# AST2600 register map
File version: 1.1
CPU: CM3 r1p0, little endian, no MPU, no FPU, 3 interrupt priority bits
Registers are 32-bit, read-write, reset 0x0 unless marked. A register's access mark holds for its fields unless they carry their own. Offsets are from the block's base; [hi:lo] are bit positions; lines under a group give offsets from that group; {n}, {i} and the like mark numbered series.

## SCB — System Control Block
Base 0xE000ED00
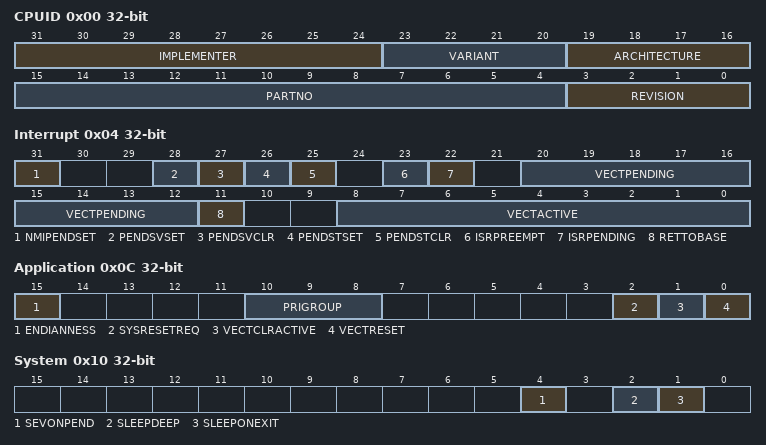
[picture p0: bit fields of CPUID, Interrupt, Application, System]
0x00 CPUID Base Register ro — Provides identification information for the processor
  [31:24] IMPLEMENTER — Implementer code assigned by ARM
  [23:20] VARIANT — IMPLEMENTATION DEFINED variant number
  [19:16] ARCHITECTURE — Reads as 0xF
  [15:4] PARTNO — IMPLEMENTATION DEFINED part number
  [3:0] REVISION — IMPLEMENTATION DEFINED revision number
0x04 Interrupt Control and State Register — Provides software control of the NMI, PendSV, and SysTick exceptions, and provides interrupt status information
  [31] NMIPENDSET — On writes, makes the NMI exception active
  [28] PENDSVSET — On writes, sets the PendSV exception as pending
  [27] PENDSVCLR — Removes the pending status of the PendSV exception
  [26] PENDSTSET — On writes, sets the SysTick exception as pending
  [25] PENDSTCLR — Removes the pending status of the SysTick exception
  [23] ISRPREEMPT — Indicates whether a pending exception will be serviced on exit from debug halt state
  [22] ISRPENDING — Indicates whether an external interrupt, generated by the NVIC, is pending
  [20:12] VECTPENDING — The exception number of the highest priority pending and enabled interrupt
  [11] RETTOBASE — In Handler mode, indicates whether there is an active exception other than the exception indicated by the current value of the IPSR
  [8:0] VECTACTIVE — The exception number of the current executing exception
0x08 Vector Table Offset Register — Holds the vector table address
  [31:7] TBLOFF — Bits[31:7] of the vector table address
0x0C Application Interrupt and Reset Control Register — Sets or returns interrupt control data
  [15] ENDIANNESS — Indicates the memory system endianness
  [10:8] PRIGROUP — Priority grouping, indicates the binary point position
  [2] SYSRESETREQ — System Reset Request
  [1] VECTCLRACTIVE — Writing 1 to this bit clears all active state information for fixed and configurable exceptions
  [0] VECTRESET — Writing 1 to this bit causes a local system reset
0x10 System Control Register — Sets or returns system control data
  [4] SEVONPEND — Determines whether an interrupt transition from inactive state to pending state is a wakeup event
  [2] SLEEPDEEP — Provides a qualifying hint indicating that waking from sleep might take longer
  [1] SLEEPONEXIT — Determines whether, on an exit from an ISR that returns to the base level of execution priority, the processor enters a sleep state
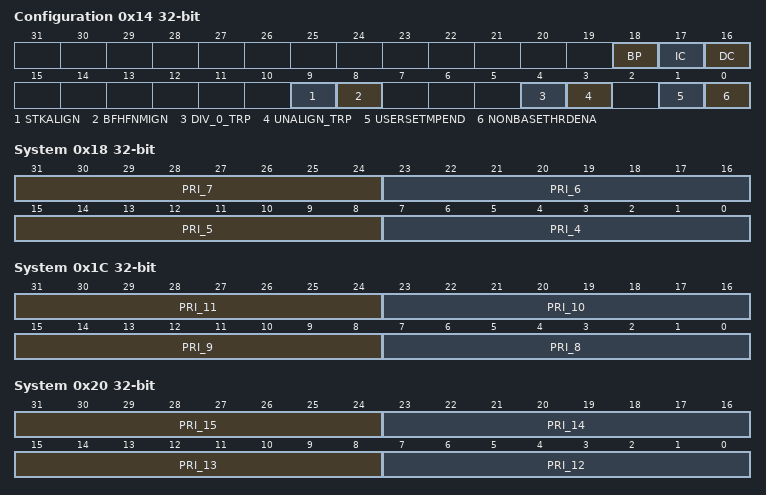
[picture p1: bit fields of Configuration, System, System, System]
0x14 Configuration and Control Register — Sets or returns configuration and control data, and provides control over caching and branch prediction
  [18] BP — Branch prediction enable bit
  [17] IC — Instruction cache enable bit
  [16] DC — Cache enable bit
  [9] STKALIGN — Determines whether the exception entry sequence guarantees 8-byte stack frame alignment, adjusting the SP if necessary before saving state
  [8] BFHFNMIGN — Determines the effect of precise data access faults on handlers running at priority -1 or priority -2
  [4] DIV_0_TRP — Controls the trap on divide by 0
  [3] UNALIGN_TRP — Controls the trapping of unaligned word or halfword accesses
  [1] USERSETMPEND — Controls whether unprivileged software can access the STIR
  [0] NONBASETHRDENA — Controls whether the processor can enter Thread mode with exceptions active
0x18 System Handler Priority Register 1 — Sets or returns priority for system handlers 4-7
  [31:24] PRI_7 — Reserved for priority of system handler 7
  [23:16] PRI_6 — Priority of system handler 6, UsageFault
  [15:8] PRI_5 — Priority of system handler 5, BusFault
  [7:0] PRI_4 — Priority of system handler 4, MemManage
0x1C System Handler Priority Register 2 — Sets or returns priority for system handlers 8-11
  [31:24] PRI_11 — Priority of system handler 11, SVCall
  [23:16] PRI_10 — Reserved for priority of system handler 10
  [15:8] PRI_9 — Reserved for priority of system handler 9
  [7:0] PRI_8 — Reserved for priority of system handler 8
0x20 System Handler Priority Register 3 — Sets or returns priority for system handlers 12-15
  [31:24] PRI_15 — Priority of system handler 15, SysTick
  [23:16] PRI_14 — Priority of system handler 14, PendSV
  [15:8] PRI_13 — Reserved for priority of system handler 13
  [7:0] PRI_12 — Priority of system handler 12, DebugMonitor
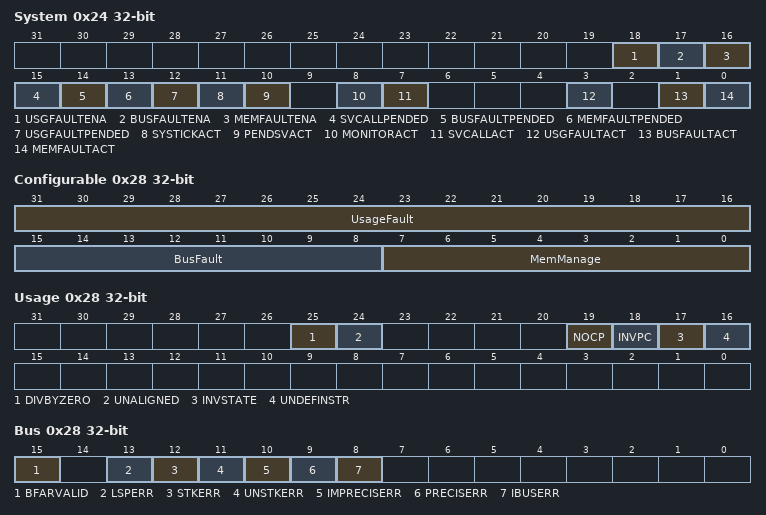
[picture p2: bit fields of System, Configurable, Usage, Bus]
0x24 System Handler Control and State Register — Controls and provides the active and pending status of system exceptions
  [18] USGFAULTENA — UsageFault exception enable
  [17] BUSFAULTENA — BusFault exception enable
  [16] MEMFAULTENA — MemManage exception enable
  [15] SVCALLPENDED — SVCall exception pended state
  [14] BUSFAULTPENDED — BusFault exception pended state
  [13] MEMFAULTPENDED — MemManage exception pended state
  [12] USGFAULTPENDED — UsageFault exception pended state
  [11] SYSTICKACT — SysTick exception active state
  [10] PENDSVACT — PendSV exception active state
  [8] MONITORACT — DebugMonitor exception active state
  [7] SVCALLACT — SVCall exception active state
  [3] USGFAULTACT — UsageFault exception active state
  [1] BUSFAULTACT — BusFault exception active state
  [0] MEMFAULTACT — MemManage exception active state
0x28 Configurable Fault Status Register — Contains the three Configurable Fault Status Registers
  [31:16] UsageFault — Provides information on UsageFault exceptions
  [15:8] BusFault — Provides information on BusFault exceptions
  [7:0] MemManage — Provides information on MemManage exceptions
0x28 Usage Fault Status Register — Provides information on UsageFault exceptions
  [25] DIVBYZERO — Divide by zero flag. Indicates whether an integer division by zero error has occurred
  [24] UNALIGNED — Unaligned access flag. Indicates whether an unaligned access error has occurred
  [19] NOCP — No coprocessor flag. Indicates whether a coprocessor disabled or not present error has occurred
  [18] INVPC — Invalid PC flag. Indicates whether an integrity check error has occurred
  [17] INVSTATE — Invalid state flag. Indicates whether an EPSR.T or EPSR.IT validity error has occurred
  [16] UNDEFINSTR — Undefined instruction flag. Indicates whether an undefined instruction error has occurred
0x28 Bus Fault Status Register — Provides information on BusFault exceptions
  [15] BFARVALID — BFAR valid. Indicates validity of the contents of the BFAR register
  [13] LSPERR — Lazy state preservation error. Records whether a BusFault occurred during FP lazy state preservation
  [12] STKERR — Stack error. Records whether a derived BusFault occurred during exception entry stacking
  [11] UNSTKERR — Unstack error. Records whether a derived BusFault occurred during exception return unstacking
  [10] IMPRECISERR — Imprecise error. Records whether an imprecise data access error has occurred
  [9] PRECISERR — Precise error. Records whether a precise data access error has occurred
  [8] IBUSERR — Instruction bus error. Records whether a BusFault on an instruction prefetch has occurred
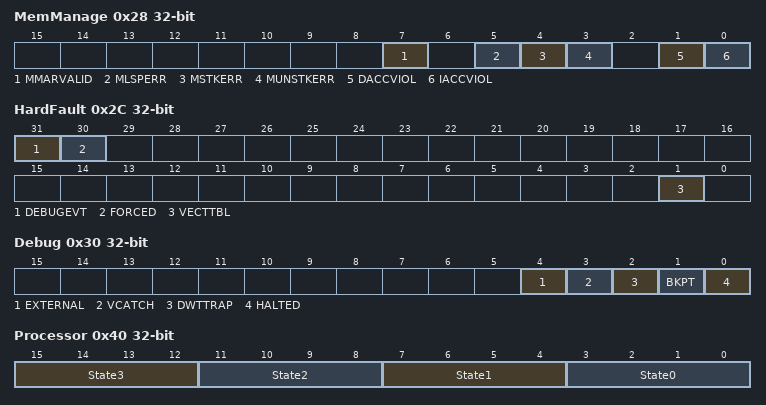
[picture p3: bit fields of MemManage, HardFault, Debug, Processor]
0x28 MemManage Fault Status Register — Provides information on MemManage exceptions
  [7] MMARVALID — MMFAR valid flag. Indicates validity of the MMFAR register
  [5] MLSPERR — MemManage lazy state preservation error flag. Records whether a MemManage fault occurred during FP lazy state preservation
  [4] MSTKERR — MemManage stacking error flag. Records whether a derived MemManage fault occurred during exception entry stacking
  [3] MUNSTKERR — MemManage unstacking error flag. Records whether a derived MemManage fault occurred during exception return unstacking
  [1] DACCVIOL — Data access violation flag. Records whether a data access violation has occurred
  [0] IACCVIOL — Instruction access violation. Records whether an instruction related memory access violation has occurred
0x2C HardFault Status Register — Shows the cause of any HardFault
  [31] DEBUGEVT — Indicates that a debug event has occurred
  [30] FORCED — Indicates that a fault with configurable priority has been escalated to a HardFault exception, because it could not be made active, because of priority or because it was disabled
  [1] VECTTBL — Indicates when a fault has occurred because of a vector table read error on exception processing
0x30 Debug Fault Status Register — Shows which debug event occurred
  [4] EXTERNAL — External event. Indicates whether an external debug request has occurred
  [3] VCATCH — Vector Catch event. Indicates whether a Vector catch debug event has occurred
  [2] DWTTRAP — Watchpoint event. Indicates whether a Watchpoint debug event has occurred
  [1] BKPT — Breakpoint event. Indicates whether a breakpoint debug event has occurred
  [0] HALTED — Halt or step event. Indicates that a Halt request debug event or Step debug event has occurred
0x34 MemManage Fault Address Register — Shows the address of the memory location that caused an MPU fault
0x38 BusFault Address Register — Shows the address associated with a precise data access BusFault
0x3C Auxiliary Fault Status Register — Provides implementation-specific fault status information and control
0x40 Processor Feature Register 0 ro — Gives top-level information about the instruction sets supported by the processor
  [15:12] State3 — ARMv7-M reserved
  [11:8] State2 — ARMv7-M reserved
  [7:4] State1 — Thumb instruction set support
  [3:0] State0 — ARM instruction set support
0x44 Processor Feature Register 1 ro — Gives top-level information about the instruction sets supported by the processor
  [11:8] M profile programmers model
0x48 Debug Feature Register 0 ro — Gives top-level information about the debug system used in the processor
  [23:20] Debug model, M profile — Support for memory-mapped debug model for M profile processors
0x4C Auxiliary Feature Register 0 ro — Gives information about the IMPLEMENTATION DEFINED features of a processor implementation
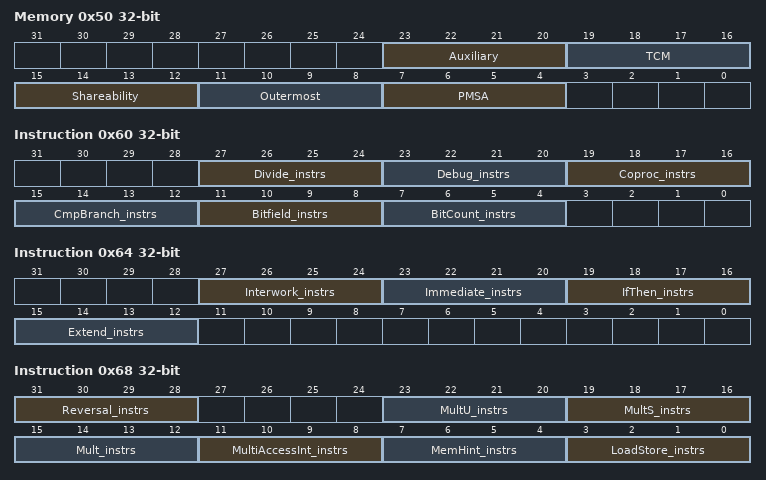
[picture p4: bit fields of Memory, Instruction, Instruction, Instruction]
0x50 Memory Model Feature Register 0 ro — Gives information about the implemented memory model and memory management support
  [23:20] Auxiliary registers — Indicates the support for Auxiliary registers
  [19:16] TCM support — Indicates the support for Tightly Coupled Memory (TCM)
  [15:12] Shareability levels — Indicates the number of shareability levels implemented
  [11:8] Outermost shareability — Indicates the outermost shareability domain implemented
  [7:4] PMSA support — Indicates support for a PMSA
0x54 Memory Model Feature Register 1 ro — Gives information about the implemented memory model and memory management support
0x58 Memory Model Feature Register 2 ro — Gives information about the implemented memory model and memory management support
  [27:24] WFI stall — Indicates the support for Wait For Interrupt (WFI) stalling
0x5C Memory Model Feature Register 3 ro — Gives information about the implemented memory model and memory management support
0x60 Instruction Set Attribute Register 0 ro — Gives information about the instruction sets implemented by the processor
  [27:24] Divide_instrs — Indicates the supported Divide instructions
  [23:20] Debug_instrs — Indicates the supported Debug instructions
  [19:16] Coproc_instrs — Indicates the supported Coprocessor instructions
  [15:12] CmpBranch_instrs — Indicates the supported combined Compare and Branch instructions
  [11:8] Bitfield_instrs — Indicates the supported BitField instructions
  [7:4] BitCount_instrs — Indicates the supported Bit Counting instructions
0x64 Instruction Set Attribute Register 1 ro — Gives information about the instruction sets implemented by the processor
  [27:24] Interwork_instrs — Indicates the supported Interworking instructions
  [23:20] Immediate_instrs — Indicates the support for data-processing instructions with long immediates
  [19:16] IfThen_instrs — Indicates the supported IfThen instructions
  [15:12] Extend_instrs — Indicates the supported Extend instructions
0x68 Instruction Set Attribute Register 2 ro — Gives information about the instruction sets implemented by the processor
  [31:28] Reversal_instrs — Indicates the supported Reversal instructions
  [23:20] MultU_instrs — Indicates the supported advanced unsigned Multiply instructions
  [19:16] MultS_instrs — Indicates the supported advanced signed Multiply instructions
  [15:12] Mult_instrs — Indicates the supported additional Multiply instructions
  [11:8] MultiAccessInt_instrs — Indicates the support for multi-access interruptible instructions
  [7:4] MemHint_instrs — Indicates the supported Memory Hint instructions
  [3:0] LoadStore_instrs — Indicates the supported additional load and store instructions
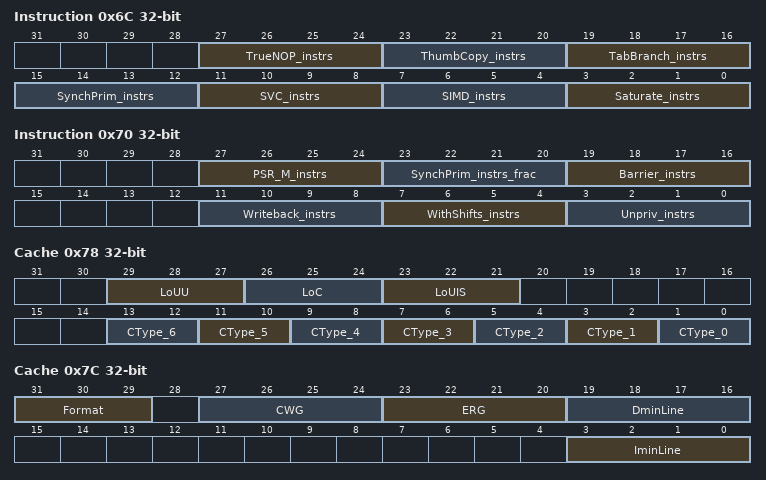
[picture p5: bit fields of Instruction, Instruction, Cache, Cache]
0x6C Instruction Set Attribute Register 3 ro — Gives information about the instruction sets implemented by the processor
  [27:24] TrueNOP_instrs — Indicates the support for a true NOP instruction
  [23:20] ThumbCopy_instrs — Indicates the supported non flag-setting MOV instructions
  [19:16] TabBranch_instrs — Indicates the supported Table Branch instructions
  [15:12] SynchPrim_instrs — Must be interpreted with the ID_ISAR4
  [11:8] SVC_instrs — Indicates the supported SVC instructions
  [7:4] SIMD_instrs — Indicates the supported SIMD instructions
  [3:0] Saturate_instrs — Indicates the supported Saturate instructions
0x70 Instruction Set Attribute Register 4 ro — Gives information about the instruction sets implemented by the processor
  [27:24] PSR_M_instrs — Indicates the supported M profile instructions to modify the PSRs
  [23:20] SynchPrim_instrs_frac — Must be interpreted with the ID_ISAR3
  [19:16] Barrier_instrs — Indicates the supported Barrier instructions
  [11:8] Writeback_instrs — Indicates the support for Writeback addressing modes
  [7:4] WithShifts_instrs — Indicates the support for instructions with shifts
  [3:0] Unpriv_instrs — Indicates the supported unprivileged instructions
0x78 Cache Level ID Register ro — The CLIDR identifies: ? The type of cache, or caches, implemented at each level, up to a maximum of seven levels
  [29:27] LoUU — Level of Unification Uniprocessor for the cache hierarchy
  [26:24] LoC — Level of Coherency for the cache hierarchy
  [23:21] LoUIS — Level of Unification Inner Shareable for the cache hierarchy
  [2n+1:2n] CType_{n} (n=0..6) — Indicates the type of cache implemented at each level
0x7C Cache Type Register ro — The CTR provides information about the architecture of the caches
  [31:29] Format — Indicates the implemented CTR format
  [27:24] CWG — Cache Write-back Granule
  [23:20] ERG — Exclusives Reservation Granule
  [19:16] DminLine — Log2 of the number of words in the smallest cache line of all the data caches and unified caches that are controlled by the processor
  [3:0] IminLine — Log2 of the number of words in the smallest cache line of all the instruction caches that are controlled by the processor
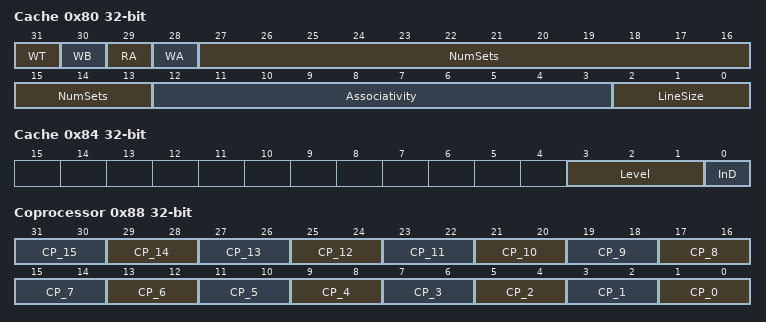
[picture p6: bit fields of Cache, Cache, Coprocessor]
0x80 Cache Size ID Registers ro — The CCSIDR provides information about the architecture of the caches
  [31] WT — Indicates whether the cache level supports write-through
  [30] WB — Indicates whether the cache level supports write-back
  [29] RA — Indicates whether the cache level supports read-allocation
  [28] WA — Indicates whether the cache level supports write-allocation
  [27:13] NumSets — (Number of sets in cache)-1, therefore a value of 0 indicates 1 set in the cache
  [12:3] Associativity — (Associativity of cache)-1, therefore a value of 0 indicates an associativity of 1
  [2:0] LineSize — (Log2(Number of words in cache line))-2
0x84 Cache Size Selection Register ro — The CSSELR selects the current CCSIDR by specifying the required cache level
  [3:1] Level — Cache level of required cache
  [0] InD — Instruction not data bit
0x88 Coprocessor Access Control Register — Specifies the access privileges for coprocessors
  [2n+1:2n] CP_{n} (n=0..15) — for n values 0-7, 10 and 11 Access privileges for coprocessor n

## NVIC — Nested Vectored Interrupt Controller
Base 0xE000E100
{0x0+4i} Interrupt Set-Enable Register {i} (i=0..7) — Enables, or reads the enable state of a group of interrupts
{0x80+4i} Interrupt Clear-Enable Register {i} (i=0..7) — Disables, or reads the enable state of, a group of registers
{0x100+4i} Interrupt Set-Pending Register {i} (i=0..7) — For a group of interrupts, changes interrupt status to pending, or shows the current pending status
{0x180+4i} Interrupt Clear-Pending Register {i} (i=0..7) — For a group of interrupts, clears the interrupt pending status, or shows the current pending status
{0x200+4i} Interrupt Active Bit Register {i} (i=0..7) ro — For a group of 32 interrupts, shows whether each interrupt is active
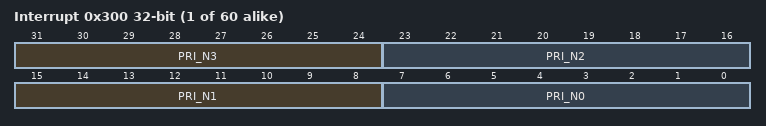
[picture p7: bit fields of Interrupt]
{0x300+4i} Interrupt Priority Register {i} (i=0..59) — Sets or reads interrupt priorities
  [31:24] PRI_N3 — For register NVIC_IPRn, priority of interrupt number 4n+3
  [23:16] PRI_N2 — For register NVIC_IPRn, priority of interrupt number 4n+2
  [15:8] PRI_N1 — For register NVIC_IPRn, priority of interrupt number 4n+1
  [7:0] PRI_N0 — For register NVIC_IPRn, priority of interrupt number 4n
